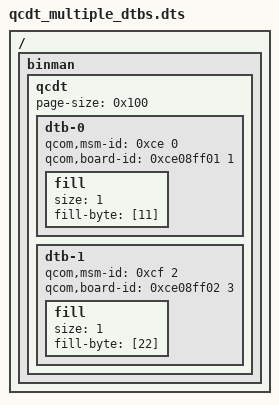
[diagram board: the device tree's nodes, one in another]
// SPDX-License-Identifier: GPL-2.0+

/dts-v1/;

/ {
	#address-cells = <1>;
	#size-cells = <1>;

	binman {
		qcdt {
			page-size = <0x100>;

			dtb-0 {
				qcom,msm-id = <0xce 0>;
				qcom,board-id = <0xce08ff01 1>;

				fill {
					size = <1>;
					fill-byte = [11];
				};
			};

			dtb-1 {
				qcom,msm-id = <0xcf 2>;
				qcom,board-id = <0xce08ff02 3>;

				fill {
					size = <1>;
					fill-byte = [22];
				};
			};
		};
	};
};
